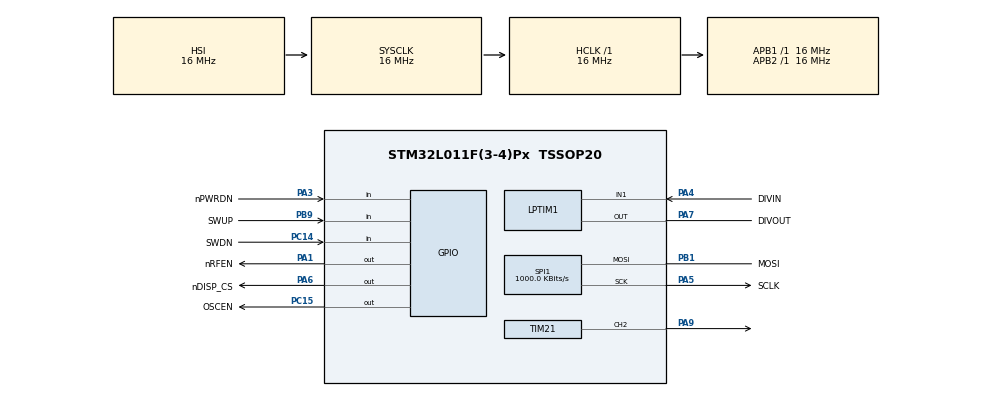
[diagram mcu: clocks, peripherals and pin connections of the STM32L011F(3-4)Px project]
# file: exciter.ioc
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Mcu.Family=STM32L0
Mcu.Name=STM32L011F(3-4)Px
Mcu.Package=TSSOP20
PA0-CK_IN.GPIO_Label=CLK
PA0-CK_IN.Mode=HSE-External-Clock-Source-for-TinyNemo
PA0-CK_IN.Signal=RCC_CK_IN
PA1.GPIO_Label=nRFEN
PA1.PinState=GPIO_PIN_SET
PA1.Signal=GPIO_Output
PA10.GPIO_Label=RXD
PA10.Signal=USART2_RX
PA13.Mode=Serial_Wire
PA13.Signal=SYS_SWDIO
PA14.Mode=Serial_Wire
PA14.Signal=SYS_SWCLK
PA2.GPIO_Label=TXD
PA2.GPIO_Speed=GPIO_SPEED_FREQ_VERY_HIGH
PA2.Signal=USART2_TX
PA3.GPIO_Label=nPWRDN
PA3.GPIO_PuPd=GPIO_PULLUP
PA3.Signal=GPIO_Input
PA4.GPIO_Label=DIVIN
PA4.GPIO_PuPd=GPIO_PULLDOWN
PA4.Mode=Counts_external_clock_standalone_1X_occur1
PA4.Signal=LPTIM1_IN1
PA5.GPIO_Label=SCLK
PA5.Mode=Simplex_Bidirectional_Master
PA5.Signal=SPI1_SCK
PA6.GPIO_Label=nDISP_CS
PA6.GPIO_Speed=GPIO_SPEED_FREQ_VERY_HIGH
PA6.PinState=GPIO_PIN_RESET
PA6.Signal=GPIO_Output
PA7.GPIO_Label=DIVOUT
PA7.GPIO_Speed=GPIO_SPEED_FREQ_VERY_HIGH
PA7.Mode=WaveformGeneration
PA7.Signal=LPTIM1_OUT
PA9.GPIO_Speed=GPIO_SPEED_FREQ_MEDIUM
PA9.Signal=S_TIM21_CH2
PB1.GPIO_Label=MOSI
PB1.Mode=Simplex_Bidirectional_Master
PB1.Signal=SPI1_MOSI
PB9-BOOT0.GPIO_Label=SWUP
PB9-BOOT0.GPIO_PuPd=GPIO_PULLUP
PB9-BOOT0.Signal=GPIO_Input
PC14-OSC32_IN.GPIO_Label=SWDN
PC14-OSC32_IN.GPIO_PuPd=GPIO_PULLUP
PC14-OSC32_IN.Signal=GPIO_Input
PC15-OSC32_OUT.GPIO_Label=OSCEN
PC15-OSC32_OUT.PinState=GPIO_PIN_SET
PC15-OSC32_OUT.Signal=GPIO_Output
ProjectManager.HeapSize=0x200
ProjectManager.StackSize=0x400
ProjectManager.TargetToolchain=STM32CubeIDE
RCC.AHBFreq_Value=16000000
RCC.APB1Freq_Value=16000000
RCC.APB1TimFreq_Value=16000000
RCC.APB2Freq_Value=16000000
RCC.APB2TimFreq_Value=16000000
RCC.HCLKFreq_Value=16000000
RCC.HSE_VALUE=12000000
RCC.HSI16_VALUE=16000000
RCC.HSI_VALUE=16000000
RCC.LSE_VALUE=32768
RCC.MSI_VALUE=2097000
RCC.PLLDIV=RCC_PLLDIV_3
RCC.PLLMUL=RCC_PLLMUL_8
RCC.PLLSourceVirtual=RCC_PLLSOURCE_HSE
RCC.SYSCLKFreq_VALUE=16000000
RCC.SYSCLKSource=RCC_SYSCLKSOURCE_HSI
RCC.TimPrescaler=SYSTICK_CLKSOURCE_HCLK_DIV8
RCC.VCOOutputFreq_Value=96000000
SH.S_TIM21_CH2.0=TIM21_CH2,PWM Generation2 CH2
SPI1.BaudRatePrescaler=SPI_BAUDRATEPRESCALER_16
SPI1.CalculateBaudRate=1000.0 KBits/s
SPI1.Direction=SPI_DIRECTION_1LINE
SPI1.Mode=SPI_MODE_MASTER
SPI1.VirtualType=VM_MASTER
TIM21.Channel-PWM\ Generation2\ CH2=TIM_CHANNEL_2
TIM21.ClockDivision=TIM_CLOCKDIVISION_DIV1
TIM21.Period=1
TIM21.Prescaler=479
TIM21.Pulse-PWM\ Generation2\ CH2=1
VP_TIM21_VS_ClockSourceINT.Mode=Internal
board=custom

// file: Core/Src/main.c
/* USER CODE BEGIN Header */
/**
  ******************************************************************************
  * @file           : main.c
  * @brief          : Main program body
  ******************************************************************************
  * @attention
  *
  * <h2><center>&copy; Copyright (c) 2020 STMicroelectronics.
  * All rights reserved.</center></h2>
  *
  * This software component is licensed by ST under BSD 3-Clause license,
  * the "License"; You may not use this file except in compliance with the
  * License. You may obtain a copy of the License at:
  *                        opensource.org/licenses/BSD-3-Clause
  *
  ******************************************************************************
  */
/* USER CODE END Header */

#include "main.h"

/* USER CODE BEGIN Includes */
#include <string.h>
#include "pwrmgmt.h"
#include "uart.h"
/* USER CODE END Includes */

LPTIM_HandleTypeDef hlptim1;

SPI_HandleTypeDef hspi1;

TIM_HandleTypeDef htim21;

void SystemClock_Config(void);
static void MX_GPIO_Init(void);
static void MX_LPTIM1_Init(void);
static void MX_SPI1_Init(void);
static void MX_TIM21_Init(void);

int main(void)
{

  /* MCU Configuration--------------------------------------------------------*/

  /* Reset of all peripherals, Initializes the Flash interface and the Systick. */
  HAL_Init();

  /* Configure the system clock */
  SystemClock_Config();

  /* Initialize all configured peripherals */
  MX_GPIO_Init();
  MX_LPTIM1_Init();
  MX_SPI1_Init();
  MX_TIM21_Init();
  /* USER CODE BEGIN 2 */
  pwrmgmt_useCrystal();
  HAL_TIM_PWM_Start(&htim21, TIM_CHANNEL_2);
  HAL_LPTIM_PWM_Start(&hlptim1, 1000, 500);
  uart_init();
  /* USER CODE END 2 */

  /* Infinite loop */
  /* USER CODE BEGIN WHILE */
  const char str[] = "This is a string that is longer than 32 bytes\n";
  uint16_t length = strlen(str);

  while (1)
  {
	uart_transmit((uint8_t *)str, length);
	HAL_Delay(1000);
    /* USER CODE END WHILE */

  }
}

void SystemClock_Config(void)
{
  RCC_OscInitTypeDef RCC_OscInitStruct = {0};
  RCC_ClkInitTypeDef RCC_ClkInitStruct = {0};
  RCC_PeriphCLKInitTypeDef PeriphClkInit = {0};

  /** Configure the main internal regulator output voltage
  */
  __HAL_PWR_VOLTAGESCALING_CONFIG(PWR_REGULATOR_VOLTAGE_SCALE1);
  /** Initializes the CPU, AHB and APB busses clocks
  */
  RCC_OscInitStruct.OscillatorType = RCC_OSCILLATORTYPE_HSI;
  RCC_OscInitStruct.HSIState = RCC_HSI_ON;
  RCC_OscInitStruct.HSICalibrationValue = RCC_HSICALIBRATION_DEFAULT;
  RCC_OscInitStruct.PLL.PLLState = RCC_PLL_NONE;
  if (HAL_RCC_OscConfig(&RCC_OscInitStruct) != HAL_OK)
  {
    Error_Handler();
  }
  /** Initializes the CPU, AHB and APB busses clocks
  */
  RCC_ClkInitStruct.ClockType = RCC_CLOCKTYPE_HCLK|RCC_CLOCKTYPE_SYSCLK
                              |RCC_CLOCKTYPE_PCLK1|RCC_CLOCKTYPE_PCLK2;
  RCC_ClkInitStruct.SYSCLKSource = RCC_SYSCLKSOURCE_HSI;
  RCC_ClkInitStruct.AHBCLKDivider = RCC_SYSCLK_DIV1;
  RCC_ClkInitStruct.APB1CLKDivider = RCC_HCLK_DIV1;
  RCC_ClkInitStruct.APB2CLKDivider = RCC_HCLK_DIV1;

  if (HAL_RCC_ClockConfig(&RCC_ClkInitStruct, FLASH_LATENCY_0) != HAL_OK)
  {
    Error_Handler();
  }
  PeriphClkInit.PeriphClockSelection = RCC_PERIPHCLK_LPTIM1;
  PeriphClkInit.LptimClockSelection = RCC_LPTIM1CLKSOURCE_PCLK;

  if (HAL_RCCEx_PeriphCLKConfig(&PeriphClkInit) != HAL_OK)
  {
    Error_Handler();
  }
}

static void MX_LPTIM1_Init(void)
{

  hlptim1.Instance = LPTIM1;
  hlptim1.Init.Clock.Source = LPTIM_CLOCKSOURCE_ULPTIM;
  hlptim1.Init.Clock.Prescaler = LPTIM_PRESCALER_DIV1;
  hlptim1.Init.UltraLowPowerClock.Polarity = LPTIM_CLOCKPOLARITY_RISING;
  hlptim1.Init.UltraLowPowerClock.SampleTime = LPTIM_CLOCKSAMPLETIME_DIRECTTRANSITION;
  hlptim1.Init.Trigger.Source = LPTIM_TRIGSOURCE_SOFTWARE;
  hlptim1.Init.OutputPolarity = LPTIM_OUTPUTPOLARITY_HIGH;
  hlptim1.Init.UpdateMode = LPTIM_UPDATE_IMMEDIATE;
  hlptim1.Init.CounterSource = LPTIM_COUNTERSOURCE_EXTERNAL;
  if (HAL_LPTIM_Init(&hlptim1) != HAL_OK)
  {
    Error_Handler();
  }

}

static void MX_SPI1_Init(void)
{

  /* SPI1 parameter configuration*/
  hspi1.Instance = SPI1;
  hspi1.Init.Mode = SPI_MODE_MASTER;
  hspi1.Init.Direction = SPI_DIRECTION_1LINE;
  hspi1.Init.DataSize = SPI_DATASIZE_8BIT;
  hspi1.Init.CLKPolarity = SPI_POLARITY_LOW;
  hspi1.Init.CLKPhase = SPI_PHASE_1EDGE;
  hspi1.Init.NSS = SPI_NSS_SOFT;
  hspi1.Init.BaudRatePrescaler = SPI_BAUDRATEPRESCALER_16;
  hspi1.Init.FirstBit = SPI_FIRSTBIT_MSB;
  hspi1.Init.TIMode = SPI_TIMODE_DISABLE;
  hspi1.Init.CRCCalculation = SPI_CRCCALCULATION_DISABLE;
  hspi1.Init.CRCPolynomial = 7;
  if (HAL_SPI_Init(&hspi1) != HAL_OK)
  {
    Error_Handler();
  }

}

static void MX_TIM21_Init(void)
{

  TIM_ClockConfigTypeDef sClockSourceConfig = {0};
  TIM_MasterConfigTypeDef sMasterConfig = {0};
  TIM_OC_InitTypeDef sConfigOC = {0};

  htim21.Instance = TIM21;
  htim21.Init.Prescaler = 479;
  htim21.Init.CounterMode = TIM_COUNTERMODE_UP;
  htim21.Init.Period = 1;
  htim21.Init.ClockDivision = TIM_CLOCKDIVISION_DIV1;
  htim21.Init.AutoReloadPreload = TIM_AUTORELOAD_PRELOAD_DISABLE;
  if (HAL_TIM_Base_Init(&htim21) != HAL_OK)
  {
    Error_Handler();
  }
  sClockSourceConfig.ClockSource = TIM_CLOCKSOURCE_INTERNAL;
  if (HAL_TIM_ConfigClockSource(&htim21, &sClockSourceConfig) != HAL_OK)
  {
    Error_Handler();
  }
  if (HAL_TIM_PWM_Init(&htim21) != HAL_OK)
  {
    Error_Handler();
  }
  sMasterConfig.MasterOutputTrigger = TIM_TRGO_RESET;
  sMasterConfig.MasterSlaveMode = TIM_MASTERSLAVEMODE_DISABLE;
  if (HAL_TIMEx_MasterConfigSynchronization(&htim21, &sMasterConfig) != HAL_OK)
  {
    Error_Handler();
  }
  sConfigOC.OCMode = TIM_OCMODE_PWM1;
  sConfigOC.Pulse = 1;
  sConfigOC.OCPolarity = TIM_OCPOLARITY_HIGH;
  sConfigOC.OCFastMode = TIM_OCFAST_DISABLE;
  if (HAL_TIM_PWM_ConfigChannel(&htim21, &sConfigOC, TIM_CHANNEL_2) != HAL_OK)
  {
    Error_Handler();
  }
  HAL_TIM_MspPostInit(&htim21);

}

static void MX_GPIO_Init(void)
{
  GPIO_InitTypeDef GPIO_InitStruct = {0};

  /* GPIO Ports Clock Enable */
  __HAL_RCC_GPIOB_CLK_ENABLE();
  __HAL_RCC_GPIOC_CLK_ENABLE();
  __HAL_RCC_GPIOA_CLK_ENABLE();

  /*Configure GPIO pin Output Level */
  HAL_GPIO_WritePin(OSCEN_GPIO_Port, OSCEN_Pin, GPIO_PIN_SET);

  /*Configure GPIO pin Output Level */
  HAL_GPIO_WritePin(nRFEN_GPIO_Port, nRFEN_Pin, GPIO_PIN_SET);

  /*Configure GPIO pin Output Level */
  HAL_GPIO_WritePin(nDISP_CS_GPIO_Port, nDISP_CS_Pin, GPIO_PIN_RESET);

  /*Configure GPIO pin : SWUP_Pin */
  GPIO_InitStruct.Pin = SWUP_Pin;
  GPIO_InitStruct.Mode = GPIO_MODE_INPUT;
  GPIO_InitStruct.Pull = GPIO_PULLUP;
  HAL_GPIO_Init(SWUP_GPIO_Port, &GPIO_InitStruct);

  /*Configure GPIO pin : SWDN_Pin */
  GPIO_InitStruct.Pin = SWDN_Pin;
  GPIO_InitStruct.Mode = GPIO_MODE_INPUT;
  GPIO_InitStruct.Pull = GPIO_PULLUP;
  HAL_GPIO_Init(SWDN_GPIO_Port, &GPIO_InitStruct);

  /*Configure GPIO pin : OSCEN_Pin */
  GPIO_InitStruct.Pin = OSCEN_Pin;
  GPIO_InitStruct.Mode = GPIO_MODE_OUTPUT_PP;
  GPIO_InitStruct.Pull = GPIO_NOPULL;
  GPIO_InitStruct.Speed = GPIO_SPEED_FREQ_LOW;
  HAL_GPIO_Init(OSCEN_GPIO_Port, &GPIO_InitStruct);

  /*Configure GPIO pin : nRFEN_Pin */
  GPIO_InitStruct.Pin = nRFEN_Pin;
  GPIO_InitStruct.Mode = GPIO_MODE_OUTPUT_PP;
  GPIO_InitStruct.Pull = GPIO_NOPULL;
  GPIO_InitStruct.Speed = GPIO_SPEED_FREQ_LOW;
  HAL_GPIO_Init(nRFEN_GPIO_Port, &GPIO_InitStruct);

  /*Configure GPIO pins : TXD_Pin RXD_Pin */
  GPIO_InitStruct.Pin = TXD_Pin|RXD_Pin;
  GPIO_InitStruct.Mode = GPIO_MODE_AF_PP;
  GPIO_InitStruct.Pull = GPIO_NOPULL;
  GPIO_InitStruct.Speed = GPIO_SPEED_FREQ_VERY_HIGH;
  GPIO_InitStruct.Alternate = GPIO_AF4_USART2;
  HAL_GPIO_Init(GPIOA, &GPIO_InitStruct);

  /*Configure GPIO pin : nPWRDN_Pin */
  GPIO_InitStruct.Pin = nPWRDN_Pin;
  GPIO_InitStruct.Mode = GPIO_MODE_INPUT;
  GPIO_InitStruct.Pull = GPIO_PULLUP;
  HAL_GPIO_Init(nPWRDN_GPIO_Port, &GPIO_InitStruct);

  /*Configure GPIO pin : nDISP_CS_Pin */
  GPIO_InitStruct.Pin = nDISP_CS_Pin;
  GPIO_InitStruct.Mode = GPIO_MODE_OUTPUT_PP;
  GPIO_InitStruct.Pull = GPIO_NOPULL;
  GPIO_InitStruct.Speed = GPIO_SPEED_FREQ_VERY_HIGH;
  HAL_GPIO_Init(nDISP_CS_GPIO_Port, &GPIO_InitStruct);

}

void Error_Handler(void)
{
}

/************************ (C) COPYRIGHT STMicroelectronics *****END OF FILE****/
